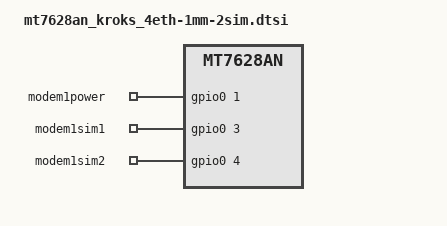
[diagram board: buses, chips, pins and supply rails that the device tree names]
/dts-v1/;

#include "mt7628an_kroks_4eth.dtsi"

/ {
	gpio_export {
		compatible = "gpio-export";
		#size-cells = <0>;

		modem1power {
			gpio-export,name = "modem1power";
			gpio-export,output = <1>;
			gpios = <&gpio0 1 GPIO_ACTIVE_HIGH>;
		};

		modem1sim1 {
			gpio-export,name = "modem1sim1";
			gpio-export,output = <1>;
			gpios = <&gpio0 3 GPIO_ACTIVE_HIGH>;
		};

		modem1sim2 {
			gpio-export,name = "modem1sim2";
			gpio-export,output = <0>;
			gpios = <&gpio0 4 GPIO_ACTIVE_HIGH>;
		};
	};
};

&state_default {
	gpio {
		ralink,group = "i2s", "i2c", "wdt", "wled_an";
		ralink,function = "gpio";
	};
};
